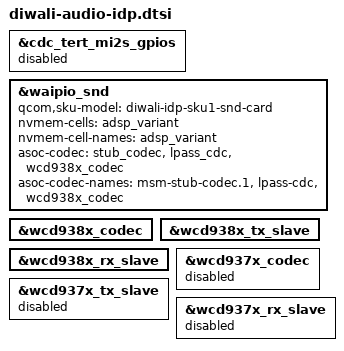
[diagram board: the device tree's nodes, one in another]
#include "diwali-audio-overlay.dtsi"

&cdc_tert_mi2s_gpios {
	status = "disabled";
};

&waipio_snd {
	qcom,sku-model = "diwali-idp-sku1-snd-card";
	nvmem-cells = <&adsp_variant>;
	nvmem-cell-names = "adsp_variant";
	asoc-codec = <&stub_codec>, <&lpass_cdc>,
		     <&wcd938x_codec>;
	asoc-codec-names = "msm-stub-codec.1", "lpass-cdc",
		           "wcd938x_codec";
};

&wcd938x_codec {
	status = "okay";
};

&wcd938x_tx_slave {
	status = "okay";
};

&wcd938x_rx_slave {
	status = "okay";
};

&wcd937x_codec {
	status = "disabled";
};

&wcd937x_tx_slave {
	status = "disabled";
};

&wcd937x_rx_slave {
	status = "disabled";
};
